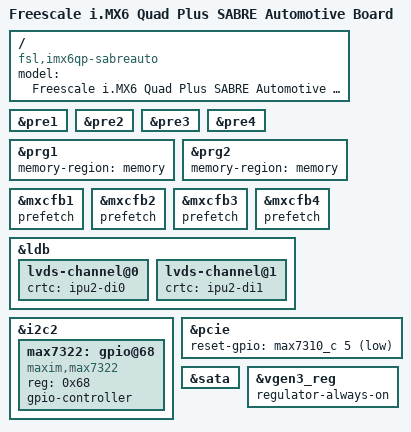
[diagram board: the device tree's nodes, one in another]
// SPDX-License-Identifier: GPL-2.0+ OR MIT
//
// Copyright 2016 Freescale Semiconductor, Inc.

/dts-v1/;

#include "imx6qp.dtsi"
#include "imx6qdl-sabreauto.dtsi"

/ {
	model = "Freescale i.MX6 Quad Plus SABRE Automotive Board";
	compatible = "fsl,imx6qp-sabreauto", "fsl,imx6qp";
};

&pre1 {
	status = "okay";
};

&pre2 {
	status = "okay";
};

&pre3 {
	status = "okay";
};

&pre4 {
	status = "okay";
};

&prg1 {
	memory-region = <&memory>;
	status = "okay";
};

&prg2 {
	memory-region = <&memory>;
	status = "okay";
};

&mxcfb1 {
	prefetch;
	status = "okay";
};

&mxcfb2 {
	prefetch;
	status = "okay";
};

&mxcfb3 {
	prefetch;
	status = "okay";
};

&mxcfb4 {
	prefetch;
	status = "okay";
};

&ldb {
	lvds-channel@0 {
		crtc = "ipu2-di0";
	};

	lvds-channel@1 {
		crtc = "ipu2-di1";
	};
};

&i2c2 {
	max7322: gpio@68 {
		compatible = "maxim,max7322";
		reg = <0x68>;
		gpio-controller;
		#gpio-cells = <2>;
	};
};

&pcie {
	reset-gpio = <&max7310_c 5 GPIO_ACTIVE_LOW>;
	status = "okay";
};

&sata {
	status = "okay";
};

&vgen3_reg {
	regulator-always-on;
};
